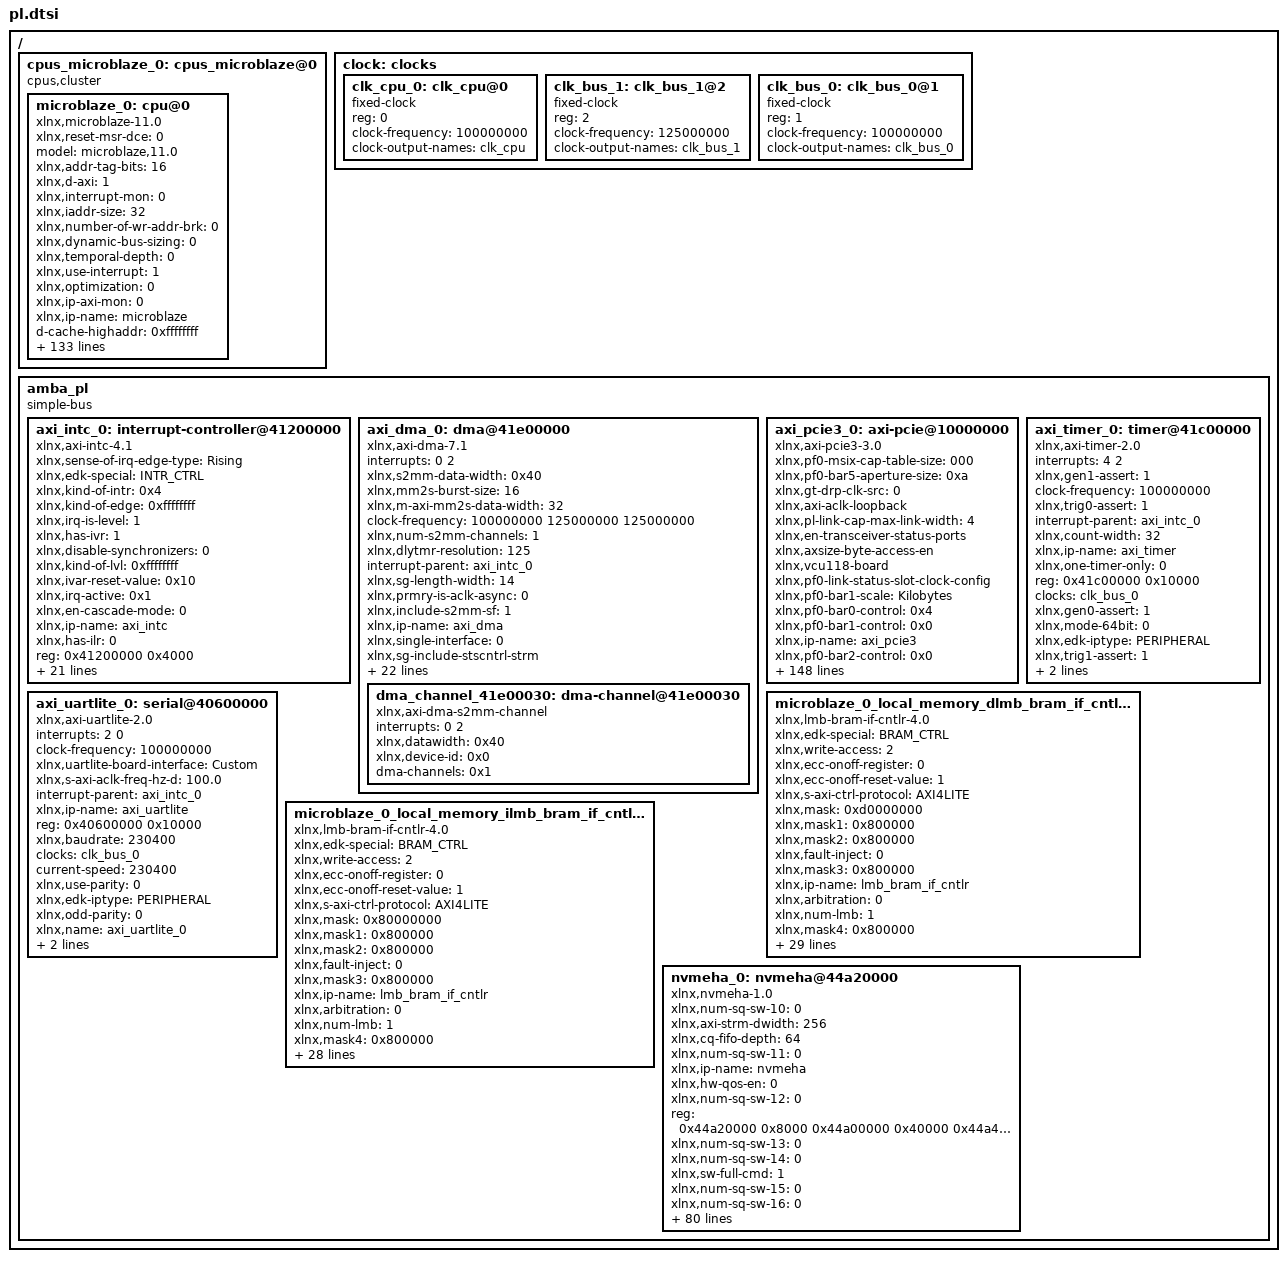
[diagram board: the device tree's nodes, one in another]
/ {
	cpus_microblaze_0: cpus_microblaze@0 {
		#cpu-mask-cells = <1>;
		compatible = "cpus,cluster";
		#address-cells = <1>;
		#size-cells = <0>;
		microblaze_0: cpu@0 {
			xlnx,reset-msr-dce = <0>;
			model = "microblaze,11.0";
			xlnx,addr-tag-bits = <16>;
			xlnx,d-axi = <1>;
			xlnx,interrupt-mon = <0>;
			xlnx,iaddr-size = <32>;
			xlnx,number-of-wr-addr-brk = <0>;
			xlnx,dynamic-bus-sizing = <0>;
			xlnx,temporal-depth = <0>;
			xlnx,use-interrupt = <1>;
			xlnx,optimization = <0>;
			xlnx,ip-axi-mon = <0>;
			xlnx,ip-name = "microblaze";
			d-cache-highaddr = <0xffffffff>;
			xlnx,dcache-force-tag-lutram = <0>;
			xlnx,pc-width = <32>;
			xlnx,interrupt-is-edge = <0>;
			reg = <0x0>;
			xlnx,async-interrupt = <1>;
			xlnx,use-mmu = <3>;
			xlnx,reset-msr-ee = <0>;
			xlnx,icache-victims = <8>;
			xlnx,use-reorder-instr = <1>;
			xlnx,d-lmb-mon = <0>;
			xlnx,d-lmb-protocol = <0>;
			xlnx,ill-opcode-exception = <1>;
			xlnx,dcache-always-used = <0>;
			xlnx,use-div = <1>;
			xlnx,dc-axi-mon = <0>;
			xlnx,debug-trace-async-reset = <0>;
			xlnx,trace = <0>;
			xlnx,part = "xcku040-ffva1156-2-i";
			i-cache-baseaddr = <0x80000000>;
			xlnx,use-config-reset = <0>;
			xlnx,pvr = <2>;
			xlnx,i-lmb-mon = <0>;
			xlnx,dcache-byte-size = <32768>;
			xlnx,fault-tolerant = <0>;
			xlnx,family = "kintexu";
			compatible = "xlnx,microblaze-11.0" , "xlnx,microblaze";
			xlnx,data-size = <32>;
			xlnx,mmu-zones = <2>;
			xlnx,debug-trace-size = <8192>;
			xlnx,mmu-privileged-instr = <0>;
			xlnx,enable-discrete-ports = <0>;
			d-cache-line-size = <16>;
			xlnx,d-lmb = <1>;
			xlnx,sco = <0>;
			xlnx,reset-msr-eip = <0>;
			xlnx,debug-interface = <0>;
			clock-frequency = <100000000>;
			xlnx,use-ext-brk = <0>;
			xlnx,daddr-size = <32>;
			xlnx,debug-enabled = <1>;
			xlnx,reset-msr-ice = <0>;
			xlnx,num-sync-ff-dbg-trace-clk = <2>;
			xlnx,i-lmb-protocol = <0>;
			xlnx,endianness = <1>;
			xlnx,fsl-exception = <0>;
			i-cache-line-size = <32>;
			xlnx,use-extended-fsl-instr = <0>;
			xlnx,reset-msr = <0x0>;
			xlnx,dp-axi-mon = <0>;
			device_type = "cpu";
			xlnx,branch-target-cache-size = <0>;
			xlnx,dcache-use-writeback = <0>;
			xlnx,div-zero-exception = <1>;
			xlnx,mmu-tlb-access = <3>;
			bus-handle = <&amba_pl>;
			xlnx,cache-byte-size = <32768>;
			xlnx,pvr-user2 = <0x0>;
			xlnx,opcode-0x0-illegal = <1>;
			xlnx,icache-line-len = <8>;
			xlnx,ecc-use-ce-exception = <0>;
			xlnx,base-vectors = <0x0>;
			xlnx,d-lmb-has-prot = <0>;
			xlnx,edk-special = "microblaze";
			xlnx,use-dcache = <1>;
			xlnx,use-barrel = <1>;
			xlnx,reset-msr-bip = <0>;
			xlnx,allow-dcache-wr = <1>;
			xlnx,debug-external-trace = <0>;
			xlnx,addr-size = <32>;
			xlnx,piaddr-size = <32>;
			i-cache-highaddr = <0xffffffff>;
			xlnx,num-sync-ff-clk-debug = <2>;
			xlnx,debug-event-counters = <5>;
			xlnx,fpu-exception = <0>;
			xlnx,allow-icache-wr = <1>;
			xlnx,g-use-exceptions = <1>;
			xlnx,i-axi = <0>;
			xlnx,g-template-list = <4>;
			xlnx,icache-streams = <1>;
			xlnx,dcache-line-len = <4>;
			xlnx,num-sync-ff-clk = <2>;
			xlnx,edk-iptype = "PROCESSOR";
			xlnx,use-stack-protection = <0>;
			xlnx,use-hw-mul = <2>;
			xlnx,num-sync-ff-dbg-clk = <1>;
			xlnx,interconnect = <2>;
			xlnx,i-lmb-has-prot = <0>;
			xlnx,debug-latency-counters = <1>;
			i-cache-size = <32768>;
			xlnx,exceptions-in-delay-slots = <1>;
			xlnx,use-fpu = <0>;
			xlnx,reset-msr-ie = <0>;
			xlnx,edge-is-positive = <1>;
			xlnx,use-pcmp-instr = <1>;
			xlnx,use-icache = <1>;
			d-cache-size = <32768>;
			xlnx,memory-ip-list = "microblaze_0_local_memory_ilmb_bram_if_cntlr_memory" , "microblaze_0_local_memory_dlmb_bram_if_cntlr_memory" , "ddr4_0_memory" , "ddr4_0_memory";
			xlnx,async-wakeup = <3>;
			xlnx,use-non-secure = <0>;
			xlnx,dcache-addr-tag = <16>;
			xlnx,number-of-rd-addr-brk = <0>;
			d-cache-baseaddr = <0x80000000>;
			xlnx,area-optimized = <0>;
			xlnx,avoid-primitives = <0>;
			xlnx,lockstep-slave = <0>;
			xlnx,use-ext-nm-brk = <0>;
			xlnx,instr-size = <32>;
			interrupt-handle = <&axi_intc_0>;
			xlnx,icache-always-used = <1>;
			xlnx,i-lmb = <1>;
			xlnx,mmu-dtlb-size = <4>;
			xlnx,lockstep-select = <0>;
			xlnx,lmb-data-size = <32>;
			xlnx,ic-axi-mon = <0>;
			xlnx,enable-conversion = <0>;
			xlnx,num-sync-ff-clk-irq = <1>;
			xlnx,fsl-links = <0>;
			timebase-frequency = <100000000>;
			xlnx,icache-force-tag-lutram = <0>;
			xlnx,dcache-data-width = <0>;
			xlnx,dcache-victims = <8>;
			xlnx,use-branch-target-cache = <0>;
			xlnx,debug-profile-size = <0>;
			xlnx,unaligned-exceptions = <1>;
			xlnx,lockstep-master = <0>;
			xlnx,freq = <100000000>;
			xlnx,number-of-pc-brk = <1>;
			xlnx,mmu-itlb-size = <2>;
			xlnx,imprecise-exceptions = <0>;
			xlnx,use-msr-instr = <1>;
			xlnx,icache-data-width = <0>;
			xlnx,debug-counter-width = <32>;
		};
	};
	clock: clocks {
		#address-cells = <1>;
		#size-cells = <0>;
		clk_cpu_0: clk_cpu@0 {
			compatible = "fixed-clock";
			reg = <0>;
			clock-frequency = <100000000>;
			clock-output-names = "clk_cpu";
			#clock-cells = <0>;
		};
		clk_bus_1: clk_bus_1@2 {
			compatible = "fixed-clock";
			reg = <2>;
			clock-frequency = <125000000>;
			clock-output-names = "clk_bus_1";
			#clock-cells = <0>;
		};
		clk_bus_0: clk_bus_0@1 {
			compatible = "fixed-clock";
			reg = <1>;
			clock-frequency = <100000000>;
			clock-output-names = "clk_bus_0";
			#clock-cells = <0>;
		};
	};
	amba_pl: amba_pl {
		ranges;
		compatible = "simple-bus";
		#address-cells = <1>;
		#size-cells = <1>;
		axi_intc_0: interrupt-controller@41200000 {
			#interrupt-cells = <2>;
			xlnx,sense-of-irq-edge-type = "Rising";
			xlnx,edk-special = "INTR_CTRL";
			xlnx,kind-of-intr = <0x4>;
			xlnx,kind-of-edge = <0xffffffff>;
			xlnx,irq-is-level = <1>;
			xlnx,has-ivr = <1>;
			compatible = "xlnx,axi-intc-4.1" , "xlnx,xps-intc-1.00.a";
			xlnx,disable-synchronizers = <0>;
			xlnx,kind-of-lvl = <0xffffffff>;
			xlnx,ivar-reset-value = <0x10>;
			xlnx,irq-active = <0x1>;
			xlnx,en-cascade-mode = <0>;
			xlnx,ip-name = "axi_intc";
			xlnx,has-ilr = <0>;
			reg = <0x41200000 0x4000>;
			xlnx,addr-width = <0x20>;
			xlnx,s-axi-aclk-freq-mhz = "100.0";
			xlnx,num-sw-intr = <0>;
			xlnx,irq-connection = <0>;
			xlnx,num-intr-inputs = <0x5>;
			xlnx,has-sie = <1>;
			xlnx,enable-async = <0>;
			xlnx,has-cie = <1>;
			xlnx,num-sync-ff = <2>;
			xlnx,edk-iptype = "PERIPHERAL";
			xlnx,mb-clk-not-connected = <1>;
			xlnx,has-ipr = <1>;
			xlnx,sense-of-irq-level-type = "Active_High";
			xlnx,cascade-master = <0>;
			xlnx,processor-clk-freq-mhz = "100.0";
			status = "okay";
			xlnx,is-fast = <0x0>;
			xlnx,has-fast = <0>;
			xlnx,ivar-rst-val = <0x10>;
			interrupt-controller;
			xlnx,async-intr = <0xffffffeb>;
			xlnx,name = "axi_intc_0";
		};
		axi_dma_0: dma@41e00000 {
			interrupts = < 0 2 >;
			compatible = "xlnx,axi-dma-7.1" , "xlnx,axi-dma-1.00.a";
			xlnx,s2mm-data-width = <0x40>;
			xlnx,mm2s-burst-size = <16>;
			xlnx,m-axi-mm2s-data-width = <32>;
			clock-frequency = <100000000 125000000 125000000>;
			xlnx,num-s2mm-channels = <1>;
			xlnx,dlytmr-resolution = <125>;
			interrupt-parent = <&axi_intc_0>;
			xlnx,sg-length-width = <14>;
			xlnx,prmry-is-aclk-async = <0>;
			xlnx,include-s2mm-sf = <1>;
			#dma-cells = <1>;
			xlnx,ip-name = "axi_dma";
			xlnx,single-interface = <0>;
			xlnx,sg-include-stscntrl-strm;
			xlnx,include-s2mm-dre = <0>;
			reg = <0x41e00000 0x4000>;
			xlnx,addr-width = <32>;
			xlnx,include-s2mm = <1>;
			clocks = <&clk_bus_0 &clk_bus_1 &clk_bus_1>;
			xlnx,s-axis-s2mm-tdata-width = <64>;
			xlnx,micro-dma = <0>;
			xlnx,increase-throughput = <0>;
			xlnx,mm2s-data-width = <0x20>;
			xlnx,addrwidth = <0x20>;
			xlnx,include-sg;
			xlnx,sg-use-stsapp-length = <0>;
			xlnx,m-axis-mm2s-tdata-width = <32>;
			xlnx,edk-iptype = "PERIPHERAL";
			xlnx,s2mm-burst-size = <256>;
			xlnx,m-axi-s2mm-data-width = <64>;
			xlnx,num-mm2s-channels = <1>;
			xlnx,enable-multi-channel = <0>;
			status = "okay";
			xlnx,include-mm2s-sf = <1>;
			clock-names = "s_axi_lite_aclk" , "m_axi_sg_aclk" , "m_axi_s2mm_aclk";
			interrupt-names = "s2mm_introut";
			xlnx,include-mm2s = <0>;
			xlnx,include-mm2s-dre = <0>;
			xlnx,name = "axi_dma_0";
			dma_channel_41e00030: dma-channel@41e00030 {
				interrupts = <0 2>;
				xlnx,datawidth = <0x40>;
				xlnx,device-id = <0x0>;
				compatible = "xlnx,axi-dma-s2mm-channel";
				dma-channels = <0x1>;
			};
		};
		axi_pcie3_0: axi-pcie@10000000 {
			xlnx,pf0-msix-cap-table-size = <000>;
			xlnx,pf0-bar5-aperture-size = <0xa>;
			xlnx,gt-drp-clk-src = <0>;
			xlnx,axi-aclk-loopback;
			xlnx,pl-link-cap-max-link-width = <4>;
			xlnx,en-transceiver-status-ports;
			xlnx,axsize-byte-access-en;
			xlnx,vcu118-board;
			xlnx,pf0-link-status-slot-clock-config;
			xlnx,pf0-bar1-scale = "Kilobytes";
			xlnx,pf0-bar0-control = <0x4>;
			xlnx,pf0-bar1-control = <0x0>;
			xlnx,ip-name = "axi_pcie3";
			xlnx,pf0-bar2-control = <0x0>;
			xlnx,pf0-bar0-enabled;
			reg = <0x10000000 0x10000000 0x76000000 0x100000 0x76100000 0x100000 0x10000000 0x4000>;
			xlnx,user-clk-freq = <2>;
			xlnx,pf0-class-code = <0x60700>;
			xlnx,pf0-bar3-control = <0x0>;
			xlnx,msix-en;
			xlnx,pf0-bar5-scale = "Kilobytes";
			xlnx,pf0-bar4-control = <0x0>;
			xlnx,pf0-bar3-type = "Memory";
			xlnx,enable-ibert;
			xlnx,silicon-rev = "Production";
			xlnx,pf0-bar5-control = <0x0>;
			xlnx,pf0-revision-id = <0x0>;
			xlnx,pf0-interrupt-pin = <0x1>;
			xlnx,axibar-0 = <0x76000000>;
			xlnx,pf0-device-id = <0x8134>;
			xlnx,pf0-bar5-size = <4>;
			xlnx,pf0-bar0-aperture-size = <0xa>;
			xlnx,gt-tx-pd;
			xlnx,pr-cap-nextptr = <0x0>;
			xlnx,axibar-1 = <0x30000000>;
			xlnx,en-axi-slave-if;
			xlnx,axi-data-width = <256>;
			xlnx,axibar-2 = <0x0>;
			xlnx,type1-prefetchable-membase-memlimit = "Disabled";
			xlnx,pf0-class-code-interface = <00>;
			xlnx,pf0-bar0-type = "Memory";
			xlnx,mcap-fpga-bitstream-version = <0x0>;
			xlnx,axibar-3 = <0x0>;
			interrupt-names = "interrupt_out";
			xlnx,select-quad = "GTH_Quad_227";
			xlnx,axibar-4 = <0x0>;
			xlnx,include-baroffset-reg = <1>;
			xlnx,pf0-bar4-aperture-size = <0xa>;
			xlnx,s-axi-id-width = <4>;
			xlnx,axibar-5 = <0x0>;
			xlnx,pf0-bar2-size = <4>;
			xlnx,enable-auto-rxeq;
			compatible = "xlnx,axi-pcie3-3.0";
			xlnx,cfg-ext-if;
			xlnx,sys-rst-n-board-interface = "Custom";
			xlnx,pciebar-num = <1>;
			xlnx,ats-cap-nextptr = <0x0>;
			xlnx,pf0-subsystem-id = <0x7>;
			xlnx,axibar-num = <2>;
			xlnx,pf0-bar0-scale = "Kilobytes";
			xlnx,pciebar2axibar-1-sec = <0>;
			interrupt-parent = <&axi_intc_0>;
			xlnx,phy-lp-txpreset = <4>;
			xlnx,coreclk-freq = <250>;
			xlnx,en-axi-master-if;
			xlnx,pciebar2axibar-3-sec = <0>;
			xlnx,rx-ppm-offset = <0>;
			xlnx,pf0-sub-class-interface-menu = "CardBus_bridge";
			xlnx,mode-selection = "Advanced";
			xlnx,vu9p-board;
			xlnx,ultrascale-plus;
			xlnx,pf0-bar4-scale = "Kilobytes";
			xlnx,pciebar2axibar-5-sec = <0>;
			xlnx,m-axi-num-write = <8>;
			xlnx,pf0-vendor-id = <0x10ee>;
			xlnx,last-core-cap-addr = <0x100>;
			xlnx,pipe-sim;
			xlnx,pf0-msix-impl-locn = "External";
			xlnx,pf0-msix-cap-table-bir = "BAR_0";
			xlnx,pf0-bar5-type = "Memory";
			xlnx,axibar-highaddr-0 = <0x760fffff>;
			xlnx,axibar-highaddr-1 = <0x3fffffff>;
			status = "okay";
			xlnx,axibar-highaddr-2 = <0x0>;
			xlnx,pll-type = <2>;
			xlnx,pf0-subsystem-vendor-id = <0x10ee>;
			xlnx,pf0-msix-cap-pba-bir = "BAR_0";
			xlnx,axibar-highaddr-3 = <0x0>;
			xlnx,pf0-msi-cap-multimsgcap = <0>;
			xlnx,pf0-bar3-aperture-size = <0xa>;
			xlnx,dev-port-type = <2>;
			xlnx,timeout0-sel = <0xe>;
			xlnx,axibar-highaddr-4 = <0x0>;
			xlnx,pf0-class-code-base = <06>;
			xlnx,pf0-bar2-type = "Memory";
			xlnx,msi-enabled;
			xlnx,name = "axi_pcie3_0";
			xlnx,axibar-highaddr-5 = <0x0>;
			interrupts = < 3 2 >;
			xlnx,plltype = "QPLL1";
			xlnx,vsec-cap-addr = <0x128>;
			xlnx,pf0-base-class-menu = "Bridge_device";
			xlnx,pf0-bar4-size = <4>;
			xlnx,is-board-project = <0>;
			xlnx,timeout-mult = <0x3>;
			xlnx,axi-addr-width = <32>;
			xlnx,axisten-freq = <125>;
			xlnx,pf0-bar3-scale = "Kilobytes";
			xlnx,s-axi-num-read = <8>;
			xlnx,pf0-bar1-size = <4>;
			xlnx,comp-timeout = <0>;
			xlnx,edk-iptype = "PERIPHERAL";
			xlnx,ins-loss-nyq = <15>;
			xlnx,msix-impl-ext;
			xlnx,ins-loss-profile = "Add-in_Card";
			xlnx,pf0-bar2-aperture-size = <0xa>;
			xlnx,vendor-id = "10EE";
			xlnx,ultrascale;
			xlnx,sys-reset-polarity = <0>;
			xlnx,rx-detect = <0>;
			xlnx,pf0-class-code-sub = <07>;
			xlnx,m-axi-num-read = <8>;
			xlnx,pf0-bar4-type = "Memory";
			xlnx,pl-link-cap-max-link-speed = <4>;
			xlnx,enable-jtag-dbg;
			xlnx,pciebar2axibar-0-sec = <0>;
			xlnx,pf0-msix-cap-table-offset = <00000000>;
			xlnx,pciebar2axibar-2-sec = <0>;
			xlnx,pf0-bar2-scale = "Kilobytes";
			xlnx,pf0-bar1-type = "Memory";
			xlnx,pcie-blk-locn = <1>;
			xlnx,pciebar2axibar-4-sec = <0>;
			xlnx,shared-logic = <1>;
			xlnx,rx-ssc-ppm = <0>;
			xlnx,pf0-bar3-size = <4>;
			xlnx,core-clk-freq = <1>;
			xlnx,pf0-msi-enabled;
			xlnx,pcie-board-interface = "Custom";
			xlnx,axibar2pciebar-0 = <0x0>;
			xlnx,pciebar2axibar-0 = <0x0>;
			xlnx,no-slv-err;
			xlnx,axibar2pciebar-1 = <0x0>;
			xlnx,old-bridge-timeout = <0>;
			xlnx,pciebar2axibar-1 = <0x0>;
			xlnx,pf0-bar1-aperture-size = <0xa>;
			xlnx,axibar2pciebar-2 = <0x0>;
			xlnx,pciebar2axibar-2 = <0x0>;
			xlnx,ref-clk-freq = <0>;
			xlnx,s-axi-num-write = <8>;
			xlnx,axibar2pciebar-3 = <0x0>;
			xlnx,pciebar2axibar-3 = <0x0>;
			xlnx,pf0-bar0-size = <4>;
			xlnx,axibar2pciebar-4 = <0x0>;
			xlnx,pciebar2axibar-4 = <0x0>;
			xlnx,xlnx-ref-board = "None";
			xlnx,type1-membase-memlimit-enable = "Disabled";
			xlnx,pf0-msix-cap-pba-offset = <00000000>;
			xlnx,mcap-enablement = "NONE";
			xlnx,timeout1-sel = <0xf>;
			xlnx,pciebar2axibar-5 = <0x0>;
			xlnx,axibar2pciebar-5 = <0x0>;
			xlnx,component-name = "axi_pcie3_v3_0";
		};
		axi_timer_0: timer@41c00000 {
			interrupts = < 4 2 >;
			compatible = "xlnx,axi-timer-2.0" , "xlnx,xps-timer-1.00.a";
			xlnx,gen1-assert = <1>;
			clock-frequency = <100000000>;
			xlnx,trig0-assert = <1>;
			interrupt-parent = <&axi_intc_0>;
			xlnx,count-width = <32>;
			xlnx,ip-name = "axi_timer";
			xlnx,one-timer-only = <0>;
			reg = <0x41c00000 0x10000>;
			clocks = <&clk_bus_0>;
			xlnx,gen0-assert = <1>;
			xlnx,mode-64bit = <0>;
			xlnx,edk-iptype = "PERIPHERAL";
			status = "okay";
			xlnx,trig1-assert = <1>;
			xlnx,enable-timer2 = <1>;
			interrupt-names = "interrupt";
			xlnx,name = "axi_timer_0";
		};
		axi_uartlite_0: serial@40600000 {
			interrupts = < 2 0 >;
			compatible = "xlnx,axi-uartlite-2.0" , "xlnx,xps-uartlite-1.00.a";
			clock-frequency = <100000000>;
			xlnx,uartlite-board-interface = "Custom";
			xlnx,s-axi-aclk-freq-hz-d = "100.0";
			interrupt-parent = <&axi_intc_0>;
			xlnx,ip-name = "axi_uartlite";
			reg = <0x40600000 0x10000>;
			xlnx,baudrate = <230400>;
			clocks = <&clk_bus_0>;
			current-speed = <230400>;
			xlnx,use-parity = <0>;
			xlnx,edk-iptype = "PERIPHERAL";
			xlnx,odd-parity = <0>;
			status = "okay";
			interrupt-names = "interrupt";
			xlnx,name = "axi_uartlite_0";
			xlnx,data-bits = <8>;
			xlnx,parity = "No_Parity";
		};
		microblaze_0_local_memory_dlmb_bram_if_cntlr: lmb_bram_if_cntlr@0 {
			xlnx,edk-special = "BRAM_CTRL";
			xlnx,write-access = <2>;
			compatible = "xlnx,lmb-bram-if-cntlr-4.0" , "xlnx,axi-bram-ctrl";
			xlnx,ecc-onoff-register = <0>;
			xlnx,ecc-onoff-reset-value = <1>;
			xlnx,s-axi-ctrl-protocol = "AXI4LITE";
			xlnx,mask = <0xd0000000>;
			xlnx,mask1 = <0x800000>;
			xlnx,mask2 = <0x800000>;
			xlnx,fault-inject = <0>;
			xlnx,mask3 = <0x800000>;
			xlnx,ip-name = "lmb_bram_if_cntlr";
			xlnx,arbitration = <0>;
			xlnx,num-lmb = <1>;
			xlnx,mask4 = <0x800000>;
			reg = <0x00000000 0x2000>;
			xlnx,s-axi-ctrl-addr-width = <32>;
			xlnx,mask5 = <0x800000>;
			xlnx,ecc-status-registers = <0>;
			xlnx,prot-cfg = <0xff>;
			xlnx,mask6 = <0x800000>;
			xlnx,lmb-protocol = <0>;
			xlnx,ce-counter-width = <0>;
			xlnx,prot-cfg1 = <0xff>;
			xlnx,mask7 = <0x800000>;
			xlnx,ecc = <0>;
			xlnx,edk-iptype = "PERIPHERAL";
			xlnx,prot-cfg2 = <0xff>;
			xlnx,lmb-dwidth = <32>;
			xlnx,interconnect = <0>;
			xlnx,ce-failing-registers = <0>;
			xlnx,prot-cfg3 = <0xff>;
			xlnx,ue-failing-registers = <0>;
			xlnx,prot-cfg4 = <0xff>;
			xlnx,lmb-has-prot = <0>;
			status = "okay";
			xlnx,data-width = <32>;
			xlnx,prot-cfg5 = <0xff>;
			xlnx,s-axi-ctrl-data-width = <32>;
			xlnx,prot-cfg6 = <0xff>;
			xlnx,bram-awidth = <32>;
			xlnx,prot-cfg7 = <0xff>;
			xlnx,lmb-awidth = <32>;
			xlnx,name = "microblaze_0_local_memory_dlmb_bram_if_cntlr";
		};
		microblaze_0_local_memory_ilmb_bram_if_cntlr: microblaze_0_local_memory_ilmb_bram_if_cntlr@0 {
			xlnx,edk-special = "BRAM_CTRL";
			xlnx,write-access = <2>;
			compatible = "xlnx,lmb-bram-if-cntlr-4.0" , "xlnx,axi-bram-ctrl";
			xlnx,ecc-onoff-register = <0>;
			xlnx,ecc-onoff-reset-value = <1>;
			xlnx,s-axi-ctrl-protocol = "AXI4LITE";
			xlnx,mask = <0x80000000>;
			xlnx,mask1 = <0x800000>;
			xlnx,mask2 = <0x800000>;
			xlnx,fault-inject = <0>;
			xlnx,mask3 = <0x800000>;
			xlnx,ip-name = "lmb_bram_if_cntlr";
			xlnx,arbitration = <0>;
			xlnx,num-lmb = <1>;
			xlnx,mask4 = <0x800000>;
			reg = <0x00000000 0x2000>;
			xlnx,s-axi-ctrl-addr-width = <32>;
			xlnx,mask5 = <0x800000>;
			xlnx,ecc-status-registers = <0>;
			xlnx,prot-cfg = <0xff>;
			xlnx,mask6 = <0x800000>;
			xlnx,lmb-protocol = <0>;
			xlnx,ce-counter-width = <0>;
			xlnx,prot-cfg1 = <0xff>;
			xlnx,mask7 = <0x800000>;
			xlnx,ecc = <0>;
			xlnx,edk-iptype = "PERIPHERAL";
			xlnx,prot-cfg2 = <0xff>;
			xlnx,lmb-dwidth = <32>;
			xlnx,interconnect = <0>;
			xlnx,ce-failing-registers = <0>;
			xlnx,prot-cfg3 = <0xff>;
			xlnx,ue-failing-registers = <0>;
			xlnx,prot-cfg4 = <0xff>;
			xlnx,lmb-has-prot = <0>;
			status = "okay";
			xlnx,prot-cfg5 = <0xff>;
			xlnx,s-axi-ctrl-data-width = <32>;
			xlnx,prot-cfg6 = <0xff>;
			xlnx,bram-awidth = <32>;
			xlnx,prot-cfg7 = <0xff>;
			xlnx,lmb-awidth = <32>;
			xlnx,name = "microblaze_0_local_memory_ilmb_bram_if_cntlr";
		};
		nvmeha_0: nvmeha@44a20000 {
			xlnx,num-sq-sw-10 = <0>;
			xlnx,axi-strm-dwidth = <256>;
			xlnx,cq-fifo-depth = <64>;
			xlnx,num-sq-sw-11 = <0>;
			xlnx,ip-name = "nvmeha";
			xlnx,hw-qos-en = <0>;
			xlnx,num-sq-sw-12 = <0>;
			reg = <0x44a20000 0x8000 0x44a00000 0x40000 0x44a40000 0x10000 0x44a50000 0x10000>;
			xlnx,num-sq-sw-13 = <0>;
			xlnx,num-sq-sw-14 = <0>;
			xlnx,sw-full-cmd = <1>;
			xlnx,num-sq-sw-15 = <0>;
			xlnx,num-sq-sw-16 = <0>;
			xlnx,num-sq-sw-17 = <0>;
			xlnx,num-sq-sw-18 = <0>;
			xlnx,num-sq-sw-20 = <0>;
			xlnx,num-sq-sw-19 = <0>;
			interrupt-names = "ha_interrupt";
			xlnx,num-sq-sw-21 = <0>;
			xlnx,hw-full-cmd = <0>;
			xlnx,s-axi-id-width = <4>;
			xlnx,num-sq-sw-22 = <0>;
			xlnx,sw-qos-en = <1>;
			xlnx,sq-depth-hw = <32>;
			xlnx,num-sq-sw-23 = <0>;
			compatible = "xlnx,nvmeha-1.0";
			xlnx,statistics-en = <1>;
			xlnx,num-sq-sw-24 = <0>;
			xlnx,en-hw-if = <0>;
			xlnx,num-sq-sw-25 = <0>;
			xlnx,num-sq-sw-26 = <0>;
			interrupt-parent = <&axi_intc_0>;
			xlnx,num-sq-sw-27 = <0>;
			xlnx,num-ssd = <1>;
			xlnx,num-sq-sw-28 = <0>;
			xlnx,num-sq-sw-30 = <0>;
			xlnx,num-sq-sw-29 = <0>;
			xlnx,cq-new-db-logic = <0>;
			xlnx,num-sq-sw-31 = <0>;
			xlnx,num-sq-hw-10 = <0>;
			xlnx,num-sq-hw-11 = <0>;
			xlnx,num-sq-hw-12 = <0>;
			status = "okay";
			xlnx,num-sq-hw-13 = <0>;
			xlnx,debug-en = <0>;
			xlnx,num-sq-hw-14 = <0>;
			xlnx,num-sq-hw-15 = <0>;
			xlnx,name = "nvmeha_0";
			xlnx,num-sq-hw-16 = <0>;
			interrupts = < 1 2 >;
			xlnx,num-sq-hw-0 = <0>;
			xlnx,num-sq-hw-17 = <0>;
			xlnx,uram-avlbl = <0>;
			xlnx,num-sq-hw-1 = <0>;
			xlnx,num-sq-hw-18 = <0>;
			xlnx,num-sq-hw-19 = <0>;
			xlnx,num-sq-hw-2 = <0>;
			xlnx,num-sq-hw-20 = <0>;
			xlnx,num-sq-hw-21 = <0>;
			xlnx,num-sq-hw-3 = <0>;
			xlnx,axi-lite-dwidth = <32>;
			xlnx,num-sq-hw-22 = <0>;
			xlnx,num-sq-hw-4 = <0>;
			xlnx,num-sq-hw-23 = <0>;
			xlnx,num-sq-hw-5 = <0>;
			xlnx,num-sq-hw-24 = <0>;
			xlnx,num-sq-hw-6 = <0>;
			xlnx,sq-new-db-logic = <0>;
			xlnx,num-sq = <4>;
			xlnx,num-sq-hw-25 = <0>;
			xlnx,num-sq-hw-7 = <0>;
			xlnx,num-sq-hw-26 = <0>;
			xlnx,num-sq-hw-8 = <0>;
			xlnx,num-sq-hw-27 = <0>;
			xlnx,num-sq-hw-9 = <0>;
			xlnx,edk-iptype = "PERIPHERAL";
			xlnx,num-sq-hw-28 = <0>;
			xlnx,num-sq-hw-29 = <0>;
			xlnx,num-sq-hw-30 = <0>;
			xlnx,num-sq-hw-31 = <0>;
			xlnx,axi-mem-dwidth = <64>;
			xlnx,axi-ssd-dwidth = <128>;
			xlnx,sq-depth-sw = <64>;
			xlnx,num-sq-sw-0 = <4>;
			xlnx,num-sq-sw-1 = <0>;
			xlnx,num-sq-sw-2 = <0>;
			xlnx,num-sq-sw-3 = <0>;
			xlnx,num-sq-sw-4 = <0>;
			xlnx,num-sq-sw-5 = <0>;
			xlnx,num-sq-sw-6 = <0>;
			xlnx,num-sq-sw-7 = <0>;
			xlnx,num-sq-sw-8 = <0>;
			xlnx,num-sq-sw-9 = <0>;
			xlnx,en-sw-if = <1>;
			xlnx,s-axi-ssd-id-width = <1>;
			xlnx,axi-strm-mstr-dwidth = <128>;
		};
	};
};
